VERSION ""

NS_ :

BS_:

BU_: TrNode

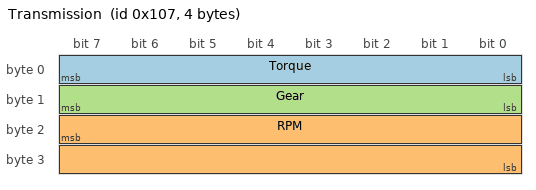
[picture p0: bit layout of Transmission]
BO_ 263 Transmission: 4 Vector__XXX
 SG_ Torque : 0|8@1+ (1,0) [0|255] "Nm" Vector__XXX
 SG_ RPM : 23|16@0+ (1,0) [0|1000] "r/s" Vector__XXX
 SG_ Gear : 8|8@1+ (1,0) [0|10] "" Vector__XXX

BA_DEF_  "BusType" STRING ;
BA_DEF_DEF_  "BusType" "CAN";
